VERSION ""

NS_ :

BS_:

BU_: Display_Screen Body_Orientation

BO_ 257 GPS: 8 Body_Orientation
 SG_ Body_Speed_mps : 0|8@1+ (0.1,0) [0|25.5] "m/s"  Display_Screen

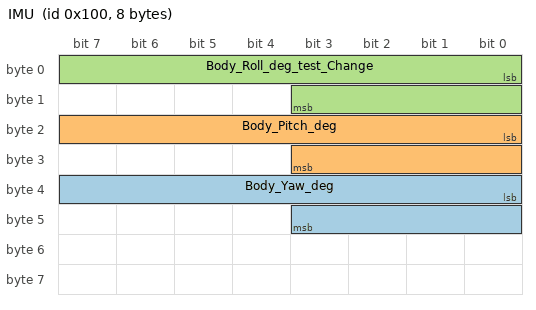
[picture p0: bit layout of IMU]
BO_ 256 IMU: 8 Body_Orientation
 SG_ Body_Yaw_deg : 32|12@1+ (0.1,0) [0|6553.5] "deg"  Display_Screen
 SG_ Body_Pitch_deg : 16|12@1+ (0.1,0) [0|409.5] "deg"  Display_Screen
 SG_ Body_Roll_deg_test_Change : 0|12@1+ (0.1,0) [0|409.5] "deg"  Display_Screen

CM_ SG_ 257 Body_Speed_mps "Velocity of the vehicle body in m/s

Resolution of 0.1 m/s (0.224 mph)";
CM_ SG_ 256 Body_Yaw_deg "Yaw angle of the vehicle body in degrees

Output is an integer to save space

Resolution of 0.1 degrees";
CM_ SG_ 256 Body_Pitch_deg "Pitch angle of the vehicle body in degrees

Output is an integer to save space

Resolution of 0.1 degrees";
CM_ SG_ 256 Body_Roll_deg_test_Change "Roll angle of the vehicle body in degrees

Output is an integer to save space

Resolution of 0.1 degrees";
BA_DEF_  "BusType" STRING ;
BA_DEF_DEF_  "BusType" "CAN";
